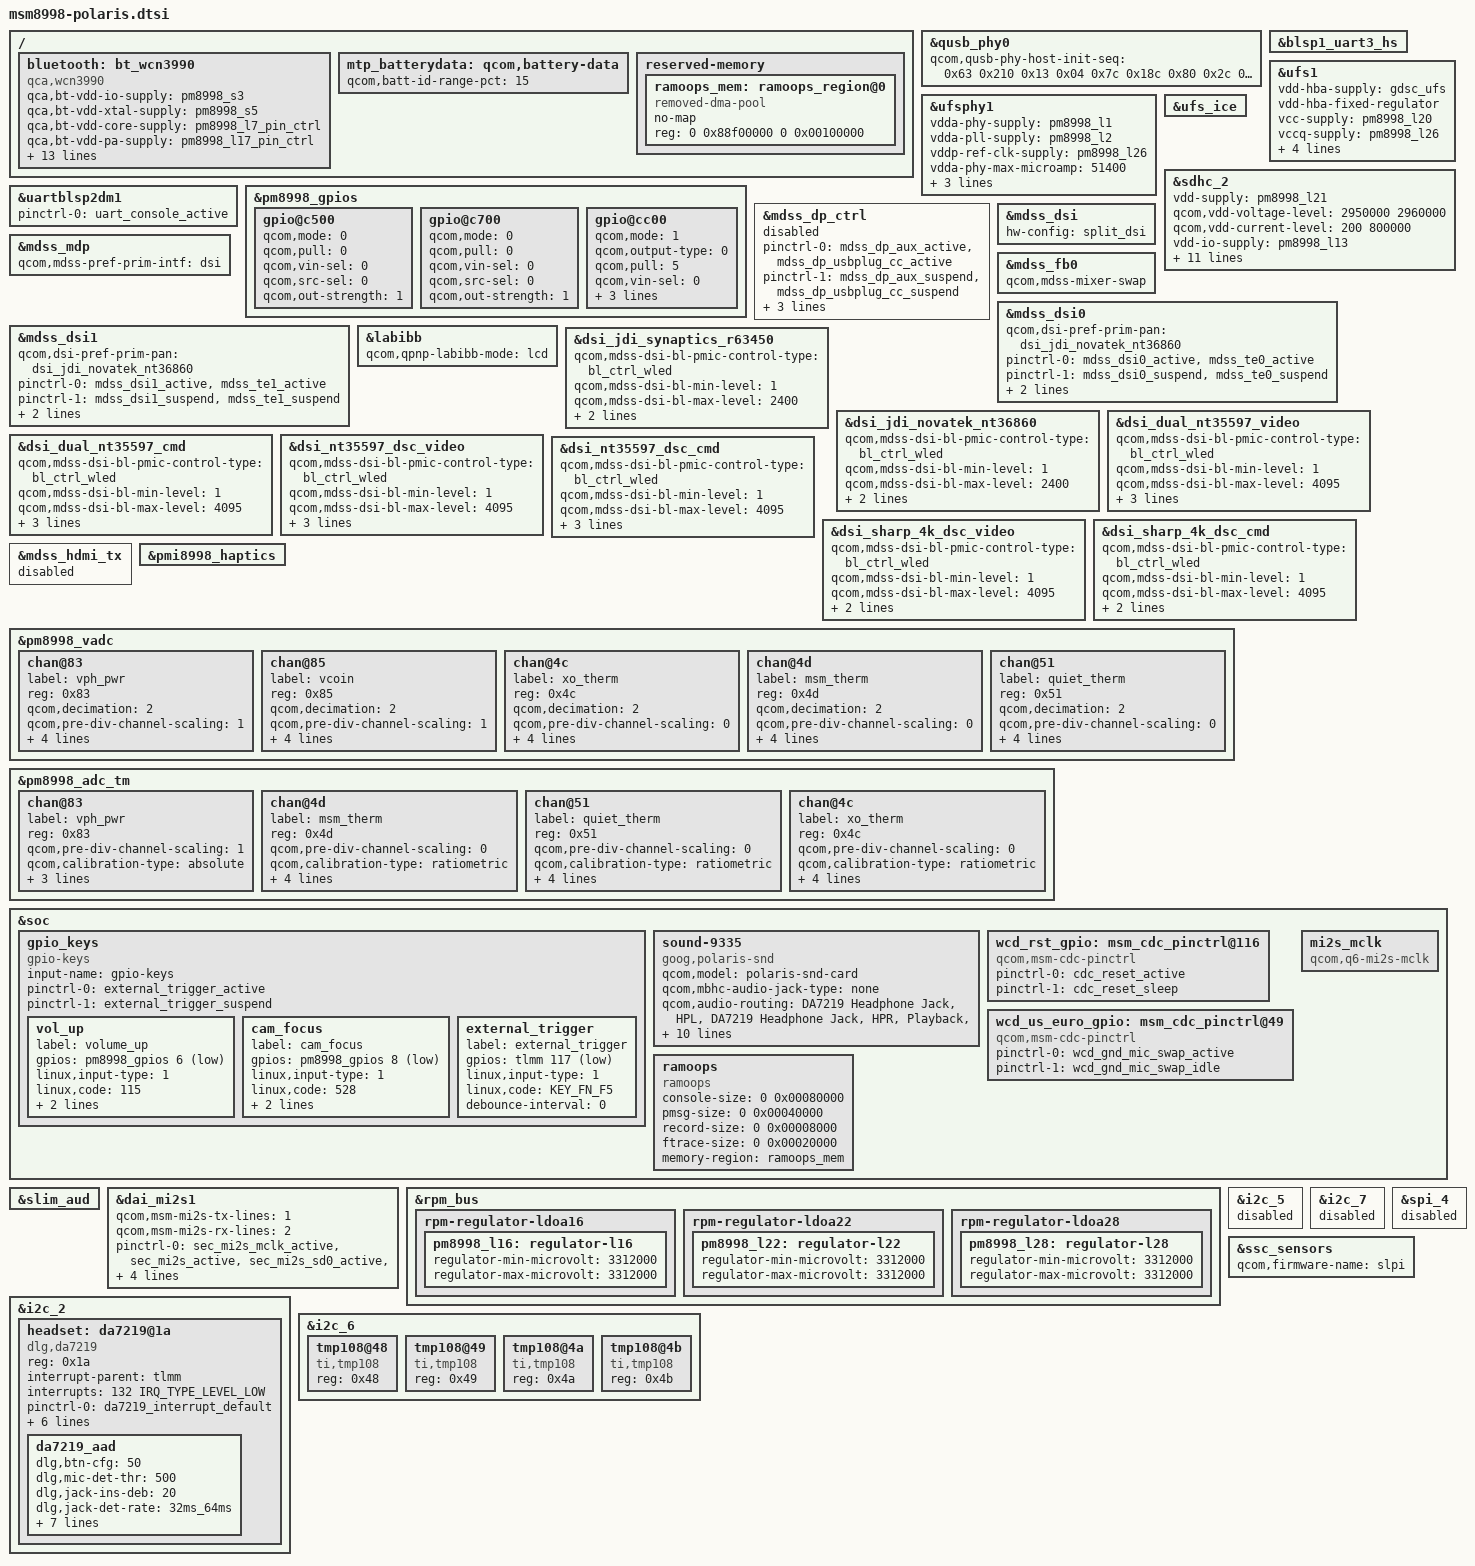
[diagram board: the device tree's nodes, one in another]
/* Copyright (c) 2016, The Linux Foundation. All rights reserved.
 *
 * This program is free software; you can redistribute it and/or modify
 * it under the terms of the GNU General Public License version 2 and
 * only version 2 as published by the Free Software Foundation.
 *
 * This program is distributed in the hope that it will be useful,
 * but WITHOUT ANY WARRANTY; without even the implied warranty of
 * MERCHANTABILITY or FITNESS FOR A PARTICULAR PURPOSE.  See the
 * GNU General Public License for more details.
 */

#include <dt-bindings/gpio/gpio.h>
#include <dt-bindings/input/input.h>

#include "dsi-panel-jdi-synaptics-r63450.dtsi"
#include "dsi-panel-jdi-novatek-nt36860.dtsi"
#include "msm8998-polaris-pinctrl.dtsi"

/ {
	bluetooth: bt_wcn3990 {
		compatible = "qca,wcn3990";
		qca,bt-vdd-io-supply = <&pm8998_s3>;
		qca,bt-vdd-xtal-supply = <&pm8998_s5>;
		qca,bt-vdd-core-supply = <&pm8998_l7_pin_ctrl>;
		qca,bt-vdd-pa-supply = <&pm8998_l17_pin_ctrl>;
		qca,bt-vdd-ldo-supply = <&pm8998_l25_pin_ctrl>;
		qca,bt-chip-pwd-supply = <&pmi8998_bob_pin1>;

		qca,bt-vdd-io-voltage-level = <1352000 1352000>;
		qca,bt-vdd-xtal-voltage-level = <2040000 2040000>;
		qca,bt-vdd-core-voltage-level = <1800000 1800000>;
		qca,bt-vdd-pa-voltage-level = <1304000 1304000>;
		qca,bt-vdd-ldo-voltage-level = <3312000 3312000>;
		qca,bt-chip-pwd-voltage-level = <3600000 3600000>;

		qca,bt-vdd-io-current-level = <1>; /* LPM/PFM */
		qca,bt-vdd-xtal-current-level = <1>; /* LPM/PFM */
		qca,bt-vdd-core-current-level = <1>; /* LPM/PFM */
		qca,bt-vdd-pa-current-level = <1>; /* LPM/PFM */
		qca,bt-vdd-ldo-current-level = <1>; /* LPM/PFM */
	};
};

&qusb_phy0 {
	qcom,qusb-phy-host-init-seq =
		/* value reg_offsets> */
		<0x63 0x210
		0x13 0x04
		0x7c 0x18c
		0x80 0x2c
		0x0a 0x184
		0x8c 0x21c
		0x05 0x23c
		0x03 0x240
		0xff 0x218
		0x62 0x210>;
};

&blsp1_uart3_hs {
	status = "ok";
};

&ufsphy1 {
	vdda-phy-supply = <&pm8998_l1>;
	vdda-pll-supply = <&pm8998_l2>;
	vddp-ref-clk-supply = <&pm8998_l26>;
	vdda-phy-max-microamp = <51400>;
	vdda-pll-max-microamp = <14600>;
	vddp-ref-clk-max-microamp = <100>;
	vddp-ref-clk-always-on;
	status = "ok";
};

&ufs1 {
	vdd-hba-supply = <&gdsc_ufs>;
	vdd-hba-fixed-regulator;
	vcc-supply = <&pm8998_l20>;
	vccq-supply = <&pm8998_l26>;
	vccq2-supply = <&pm8998_s4>;
	vcc-max-microamp = <750000>;
	vccq-max-microamp = <560000>;
	vccq2-max-microamp = <750000>;
	status = "ok";
};

&ufs_ice {
	status = "ok";
};

&sdhc_2 {
	vdd-supply = <&pm8998_l21>;
	qcom,vdd-voltage-level = <2950000 2960000>;
	qcom,vdd-current-level = <200 800000>;

	vdd-io-supply = <&pm8998_l13>;
	qcom,vdd-io-voltage-level = <1808000 2960000>;
	qcom,vdd-io-current-level = <200 22000>;

	pinctrl-names = "active", "sleep";
	pinctrl-0 = <&sdc2_clk_on  &sdc2_cmd_on &sdc2_data_on &sdc2_cd_on>;
	pinctrl-1 = <&sdc2_clk_off &sdc2_cmd_off &sdc2_data_off &sdc2_cd_off>;

	qcom,clk-rates = <400000 20000000 25000000
				50000000 100000000 200000000>;
	qcom,bus-speed-mode = "SDR12", "SDR25", "SDR50", "DDR50", "SDR104";

	cd-gpios = <&tlmm 95 0x1>;

	status = "ok";
};

&uartblsp2dm1 {
	status = "ok";
	pinctrl-names = "default";
	pinctrl-0 = <&uart_console_active>;
};

&pm8998_gpios {
	/* GPIO 6 for Vol+ Key */
	gpio@c500 {
		status = "okay";
		qcom,mode = <0>;
		qcom,pull = <0>;
		qcom,vin-sel = <0>;
		qcom,src-sel = <0>;
		qcom,out-strength = <1>;
	};

	/* GPIO 8 for Focus Key */
	gpio@c700 {
		status = "okay";
		qcom,mode = <0>;
		qcom,pull = <0>;
		qcom,vin-sel = <0>;
		qcom,src-sel = <0>;
		qcom,out-strength = <1>;
	};

	gpio@cc00 { /* GPIO 13 */
		qcom,mode = <1>;
		qcom,output-type = <0>;
		qcom,pull = <5>;
		qcom,vin-sel = <0>;
		qcom,out-strength = <1>;
		qcom,src-sel = <3>;
		qcom,master-en = <1>;
		status = "okay";
	};
};

&mdss_dp_ctrl {
	status = "disabled";
	pinctrl-names = "mdss_dp_active", "mdss_dp_sleep";
	pinctrl-0 = <&mdss_dp_aux_active &mdss_dp_usbplug_cc_active>;
	pinctrl-1 = <&mdss_dp_aux_suspend &mdss_dp_usbplug_cc_suspend>;
	qcom,aux-en-gpio = <&tlmm 77 0>;
	qcom,aux-sel-gpio = <&tlmm 78 0>;
	qcom,usbplug-cc-gpio = <&tlmm 38 0>;
};

&mdss_mdp {
	qcom,mdss-pref-prim-intf = "dsi";
};

&mdss_dsi {
	hw-config = "split_dsi";
};

&mdss_fb0 {
	qcom,mdss-mixer-swap;
};

&mdss_dsi0 {
	qcom,dsi-pref-prim-pan = <&dsi_jdi_novatek_nt36860>; /* for synaptic panel use &dsi_jdi_synaptics_r63450 */
	pinctrl-names = "mdss_default", "mdss_sleep";
	pinctrl-0 = <&mdss_dsi0_active &mdss_te0_active>;
	pinctrl-1 = <&mdss_dsi0_suspend &mdss_te0_suspend>;
	qcom,platform-reset-gpio = <&tlmm 93 0>;
	qcom,platform-te-gpio = <&tlmm 97 0>;
};

&mdss_dsi1 {
	qcom,dsi-pref-prim-pan = <&dsi_jdi_novatek_nt36860>; /* for synaptic panel use &dsi_jdi_synaptics_r63450 */
	pinctrl-names = "mdss_default", "mdss_sleep";
	pinctrl-0 = <&mdss_dsi1_active &mdss_te1_active>;
	pinctrl-1 = <&mdss_dsi1_suspend &mdss_te1_suspend>;
	qcom,platform-reset-gpio = <&tlmm 94 0>;
	qcom,platform-te-gpio = <&tlmm 98 0>;
};

&labibb {
	status = "ok";
	qcom,qpnp-labibb-mode = "lcd";
};

&dsi_jdi_synaptics_r63450 {
	qcom,mdss-dsi-bl-pmic-control-type = "bl_ctrl_wled";
	qcom,mdss-dsi-bl-min-level = <1>;
	qcom,mdss-dsi-bl-max-level = <2400>;
	qcom,panel-supply-entries = <&dsi_panel_pwr_supply>;
};

&dsi_jdi_novatek_nt36860 {
	qcom,mdss-dsi-bl-pmic-control-type = "bl_ctrl_wled";
	qcom,mdss-dsi-bl-min-level = <1>;
	qcom,mdss-dsi-bl-max-level = <2400>;
	qcom,panel-supply-entries = <&dsi_panel_pwr_supply>;
};

&dsi_dual_nt35597_video {
	qcom,mdss-dsi-bl-pmic-control-type = "bl_ctrl_wled";
	qcom,mdss-dsi-bl-min-level = <1>;
	qcom,mdss-dsi-bl-max-level = <4095>;
	qcom,mdss-dsi-mode-sel-gpio-state = "dual_port";
	qcom,panel-supply-entries = <&dsi_panel_pwr_supply>;
};

&dsi_dual_nt35597_cmd {
	qcom,mdss-dsi-bl-pmic-control-type = "bl_ctrl_wled";
	qcom,mdss-dsi-bl-min-level = <1>;
	qcom,mdss-dsi-bl-max-level = <4095>;
	qcom,mdss-dsi-mode-sel-gpio-state = "dual_port";
	qcom,panel-supply-entries = <&dsi_panel_pwr_supply>;
};

&dsi_nt35597_dsc_video {
	qcom,mdss-dsi-bl-pmic-control-type = "bl_ctrl_wled";
	qcom,mdss-dsi-bl-min-level = <1>;
	qcom,mdss-dsi-bl-max-level = <4095>;
	qcom,mdss-dsi-mode-sel-gpio-state = "single_port";
	qcom,panel-supply-entries = <&dsi_panel_pwr_supply>;
};

&dsi_nt35597_dsc_cmd {
	qcom,mdss-dsi-bl-pmic-control-type = "bl_ctrl_wled";
	qcom,mdss-dsi-bl-min-level = <1>;
	qcom,mdss-dsi-bl-max-level = <4095>;
	qcom,mdss-dsi-mode-sel-gpio-state = "single_port";
	qcom,panel-supply-entries = <&dsi_panel_pwr_supply>;
};

&dsi_sharp_4k_dsc_video {
	qcom,mdss-dsi-bl-pmic-control-type = "bl_ctrl_wled";
	qcom,mdss-dsi-bl-min-level = <1>;
	qcom,mdss-dsi-bl-max-level = <4095>;
	qcom,panel-supply-entries = <&dsi_panel_pwr_supply>;
};

&dsi_sharp_4k_dsc_cmd {
	qcom,mdss-dsi-bl-pmic-control-type = "bl_ctrl_wled";
	qcom,mdss-dsi-bl-min-level = <1>;
	qcom,mdss-dsi-bl-max-level = <4095>;
	qcom,panel-supply-entries = <&dsi_panel_pwr_supply>;
};

&mdss_hdmi_tx {
	status = "disabled";
};

&pmi8998_haptics {
	status = "okay";
};

&pm8998_vadc {
	chan@83 {
		label = "vph_pwr";
		reg = <0x83>;
		qcom,decimation = <2>;
		qcom,pre-div-channel-scaling = <1>;
		qcom,calibration-type = "absolute";
		qcom,scale-function = <0>;
		qcom,hw-settle-time = <0>;
		qcom,fast-avg-setup = <0>;
	};

	chan@85 {
		label = "vcoin";
		reg = <0x85>;
		qcom,decimation = <2>;
		qcom,pre-div-channel-scaling = <1>;
		qcom,calibration-type = "absolute";
		qcom,scale-function = <0>;
		qcom,hw-settle-time = <0>;
		qcom,fast-avg-setup = <0>;
	};

	chan@4c {
		label = "xo_therm";
		reg = <0x4c>;
		qcom,decimation = <2>;
		qcom,pre-div-channel-scaling = <0>;
		qcom,calibration-type = "ratiometric";
		qcom,scale-function = <4>;
		qcom,hw-settle-time = <2>;
		qcom,fast-avg-setup = <0>;
	};

	chan@4d {
		label = "msm_therm";
		reg = <0x4d>;
		qcom,decimation = <2>;
		qcom,pre-div-channel-scaling = <0>;
		qcom,calibration-type = "ratiometric";
		qcom,scale-function = <2>;
		qcom,hw-settle-time = <2>;
		qcom,fast-avg-setup = <0>;
	};

	chan@51 {
		label = "quiet_therm";
		reg = <0x51>;
		qcom,decimation = <2>;
		qcom,pre-div-channel-scaling = <0>;
		qcom,calibration-type = "ratiometric";
		qcom,scale-function = <2>;
		qcom,hw-settle-time = <2>;
		qcom,fast-avg-setup = <0>;
	};
};

&pm8998_adc_tm {
	chan@83 {
		label = "vph_pwr";
		reg = <0x83>;
		qcom,pre-div-channel-scaling = <1>;
		qcom,calibration-type = "absolute";
		qcom,scale-function = <0>;
		qcom,hw-settle-time = <0>;
		qcom,btm-channel-number = <0x60>;
	};

	chan@4d {
		label = "msm_therm";
		reg = <0x4d>;
		qcom,pre-div-channel-scaling = <0>;
		qcom,calibration-type = "ratiometric";
		qcom,scale-function = <2>;
		qcom,hw-settle-time = <2>;
		qcom,btm-channel-number = <0x68>;
		qcom,thermal-node;
	};

	chan@51 {
		label = "quiet_therm";
		reg = <0x51>;
		qcom,pre-div-channel-scaling = <0>;
		qcom,calibration-type = "ratiometric";
		qcom,scale-function = <2>;
		qcom,hw-settle-time = <2>;
		qcom,btm-channel-number = <0x70>;
		qcom,thermal-node;
	};

	chan@4c {
		label = "xo_therm";
		reg = <0x4c>;
		qcom,pre-div-channel-scaling = <0>;
		qcom,calibration-type = "ratiometric";
		qcom,scale-function = <4>;
		qcom,hw-settle-time = <2>;
		qcom,btm-channel-number = <0x78>;
		qcom,thermal-node;
	};
};

&soc {
	/delete-node/ msm_cdc_pinctrl@64;
	/delete-node/ msm_cdc_pinctrl@75;
	/delete-node/ sound-tavil;
	/delete-node/ qcom,wcd-dsp-mgr;

	gpio_keys {
		compatible = "gpio-keys";
		input-name = "gpio-keys";
		status = "okay";
		pinctrl-names = "tlmm_gpio_key_active", "tlmm_gpio_key_suspend";
		pinctrl-0 = <&external_trigger_active>;
		pinctrl-1 = <&external_trigger_suspend>;

		vol_up {
			label = "volume_up";
			gpios = <&pm8998_gpios 6 0x1>;
			linux,input-type = <1>;
			linux,code = <115>;
			gpio-key,wakeup;
			debounce-interval = <15>;
		};

		cam_focus {
			label = "cam_focus";
			gpios = <&pm8998_gpios 8 0x1>;
			linux,input-type = <1>;
			linux,code = <528>;
			gpio-key,wakeup;
			debounce-interval = <15>;
		};

		external_trigger: external_trigger {
			label = "external_trigger";
			gpios = <&tlmm 117 GPIO_ACTIVE_LOW>;
			linux,input-type = <1>;
			linux,code = <KEY_FN_F5>;
			debounce-interval = <0>;
		};
	};

	sound-9335 {
		/delete-property/ qcom,msm-mbhc-hphl-swh;
		/delete-property/ qcom,msm-mbhc-gnd-swh;
		/delete-property/ qcom,us-euro-gpios;

		compatible = "goog,polaris-snd";
		qcom,model = "polaris-snd-card";

		qcom,mbhc-audio-jack-type = "none";

		qcom,audio-routing =
			"DA7219 Headphone Jack", "HPL",
			"DA7219 Headphone Jack", "HPR",
			"Playback", "Secondary MI2S Playback",
			"MIC", "DA7219 Headset Mic",
			"Secondary MI2S Capture", "Capture",
			"DMIC0", "MIC BIAS1",
			"MIC BIAS1", "Digital Mic0",
			"DMIC1", "MIC BIAS1",
			"MIC BIAS1", "Digital Mic1",
			"SpkrLeft IN", "SPK1 OUT",
			"SpkrRight IN", "SPK2 OUT";

		asoc-codec = <&stub_codec>, <&ext_disp_audio_codec>, <&headset>;
		asoc-codec-names = "msm-stub-codec.1",
				   "msm-ext-disp-audio-codec-rx",
				   "da7219";
	};

	wcd_rst_gpio: msm_cdc_pinctrl@116 {
		compatible = "qcom,msm-cdc-pinctrl";
		pinctrl-names = "aud_active", "aud_sleep";
		pinctrl-0 = <&cdc_reset_active>;
		pinctrl-1 = <&cdc_reset_sleep>;
	};

	wcd_us_euro_gpio: msm_cdc_pinctrl@49 {
		compatible = "qcom,msm-cdc-pinctrl";
		pinctrl-names = "aud_active", "aud_sleep";
		pinctrl-0 = <&wcd_gnd_mic_swap_active>;
		pinctrl-1 = <&wcd_gnd_mic_swap_idle>;
	};

	mi2s_mclk: mi2s_mclk {
		compatible = "qcom,q6-mi2s-mclk";
		#clock-cells = <1>;
	};

	ramoops {
		compatible = "ramoops";
		status = "ok";
		console-size = <0 0x00080000>;
		pmsg-size = <0 0x00040000>;
		record-size = <0 0x00008000>;
		ftrace-size = <0 0x00020000>;
		memory-region = <&ramoops_mem>;
	};
};

&slim_aud {
	/delete-node/ tavil_codec;
};

&dai_mi2s1 { /* qcom,msm-dai-q6-mi2s-sec */
	qcom,msm-mi2s-tx-lines = <1>;
	qcom,msm-mi2s-rx-lines = <2>;
	pinctrl-names = "default", "idle";
	pinctrl-0 = <&sec_mi2s_mclk_active &sec_mi2s_active
		     &sec_mi2s_sd0_active &sec_mi2s_sd1_active>;
	pinctrl-1 = <&sec_mi2s_mclk_sleep &sec_mi2s_sleep
		     &sec_mi2s_sd0_sleep &sec_mi2s_sd1_sleep>;
};

/{
	mtp_batterydata: qcom,battery-data {
		qcom,batt-id-range-pct = <15>;
		#include "../qcom/fg-gen3-batterydata-itech-3000mah.dtsi"
		#include "../qcom/fg-gen3-batterydata-ascent-3450mah.dtsi"
	};
};

&rpm_bus {
	rpm-regulator-ldoa16 {
		status = "okay";
		pm8998_l16: regulator-l16 {
			regulator-min-microvolt = <3312000>;
			regulator-max-microvolt = <3312000>;
			status = "okay";
		};
	};

	rpm-regulator-ldoa22 {
		status = "okay";
		pm8998_l22: regulator-l22 {
			regulator-min-microvolt = <3312000>;
			regulator-max-microvolt = <3312000>;
			status = "okay";
		};
	};

	rpm-regulator-ldoa28 {
		status = "okay";
		pm8998_l28: regulator-l28 {
			regulator-min-microvolt = <3312000>;
			regulator-max-microvolt = <3312000>;
			status = "okay";
		};
	};
};

&i2c_2 {
	/* DA7219 Audio Codec */
	status = "okay";

	headset: da7219@1a {
		compatible = "dlg,da7219";
		reg = <0x1a>;

		interrupt-parent = <&tlmm>;
		interrupt-names = "irq";
		interrupts = <132 IRQ_TYPE_LEVEL_LOW>;

		pinctrl-names = "default";
		pinctrl-0 = <&da7219_interrupt_default>;

		VDD-supply = <&pm8998_s4>;
		VDDIO-supply = <&pm8998_s4>;
		VDDMIC-supply = <&pm8998_l18>;

		dlg,micbias-lvl = <2600>;
		dlg,mic-amp-in-sel = "diff";

		clocks = <&mi2s_mclk clk_sec_mi2s_mclk>;
		clock-names = "mclk";

		da7219_aad {
			dlg,btn-cfg = <50>;
			dlg,mic-det-thr = <500>;
			dlg,jack-ins-deb = <20>;
			dlg,jack-det-rate = "32ms_64ms";
			dlg,jack-rem-deb = <1>;

			dlg,a-d-btn-thr = <0xa>;
			dlg,d-b-btn-thr = <0x16>;
			dlg,b-c-btn-thr = <0x21>;
			dlg,c-mic-btn-thr = <0x3E>;

			dlg,btn-avg = <4>;
			dlg,adc-1bit-rpt = <1>;
		};
	};
};

&i2c_5 {
	/* Display controller. */
	status = "disabled";
};

&i2c_6 {
	/* Thermal sensors. */
	status = "okay";

	tmp108@48 {
		/* U32 - Near MSM8998 */
		compatible = "ti,tmp108";
		reg = <0x48>;
	};

	tmp108@49 {
		/* U33 - Near PM8998 */
		compatible = "ti,tmp108";
		reg = <0x49>;
	};

	tmp108@4a {
		/* U34 - Near PMI8998 */
		compatible = "ti,tmp108";
		reg = <0x4a>;
	};

	tmp108@4b {
		/* U35 - Near UFS */
		compatible = "ti,tmp108";
		reg = <0x4b>;
	};
};

&i2c_7 {
	/* "A00" battery connector, SMB1380 charger. */
	status = "disabled";
};

&spi_4 {
	/* SPI */
	status = "disabled";
};

/ {
	reserved-memory {
		ramoops_mem: ramoops_region@0 {
			compatible = "removed-dma-pool";
			no-map;
			reg = <0 0x88f00000 0 0x00100000>;
		};
    };
};

&ssc_sensors {
	/* SLPI firmware files are spli.* */
	qcom,firmware-name = "slpi";
};
